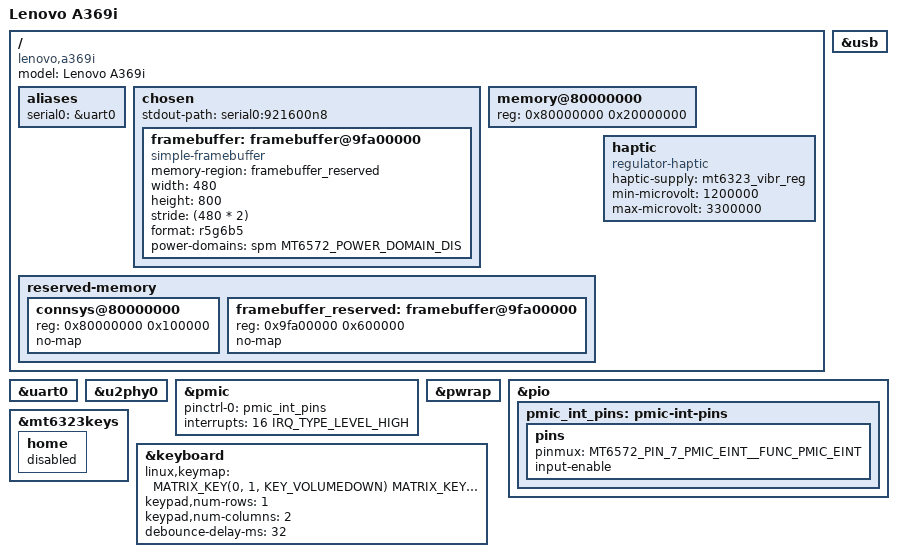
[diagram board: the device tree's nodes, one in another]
// SPDX-License-Identifier: GPL-2.0
/*
 * Copyright (c) 2025 Max Shevchenko <wctrl@proton.me>
 */

/dts-v1/;
#include <dt-bindings/input/input.h>
#include "mt6572.dtsi"
#include "mt6323.dtsi"

/ {
	model = "Lenovo A369i";
	compatible = "lenovo,a369i", "mediatek,mt6572";

	aliases {
		serial0 = &uart0;
	};

	chosen {
		#address-cells = <1>;
		#size-cells = <1>;
		stdout-path = "serial0:921600n8";

		framebuffer: framebuffer@9fa00000 {
			compatible = "simple-framebuffer";
			memory-region = <&framebuffer_reserved>;
			width = <480>;
			height = <800>;
			stride = <(480 * 2)>;
			format = "r5g6b5";
			power-domains = <&spm MT6572_POWER_DOMAIN_DIS>;
		};
	};

	memory@80000000 {
		device_type = "memory";
		reg = <0x80000000 0x20000000>;
	};

	reserved-memory {
		#address-cells = <1>;
		#size-cells = <1>;
		ranges;

		connsys@80000000 {
			reg = <0x80000000 0x100000>;
			no-map;
		};

		framebuffer_reserved: framebuffer@9fa00000 {
			reg = <0x9fa00000 0x600000>;
			no-map;
		};
	};

	haptic {
		compatible = "regulator-haptic";
		haptic-supply = <&mt6323_vibr_reg>;
		min-microvolt = <1200000>;
		max-microvolt = <3300000>;
	};
};

&uart0 {
	status = "okay";
};

&usb {
	status = "okay";
};

&u2phy0 {
	status = "okay";
};

&pmic {
	pinctrl-0 = <&pmic_int_pins>;
	pinctrl-names = "default";
	interrupts = <16 IRQ_TYPE_LEVEL_HIGH>;
};

&pwrap {
	pinctrl-names = "default";
};

&pio {
	pmic_int_pins: pmic-int-pins {
		pins {
			pinmux = <MT6572_PIN_7_PMIC_EINT__FUNC_PMIC_EINT>;
			input-enable;
		};
	};
};

&mt6323keys {
	home {
		status = "disabled";
	};
};

&keyboard {
	status = "okay";
	linux,keymap = <MATRIX_KEY(0, 1, KEY_VOLUMEDOWN)
			MATRIX_KEY(0, 2, KEY_VOLUMEUP)>;
	keypad,num-rows = <1>;
	keypad,num-columns = <2>;
	debounce-delay-ms = <32>;
};
